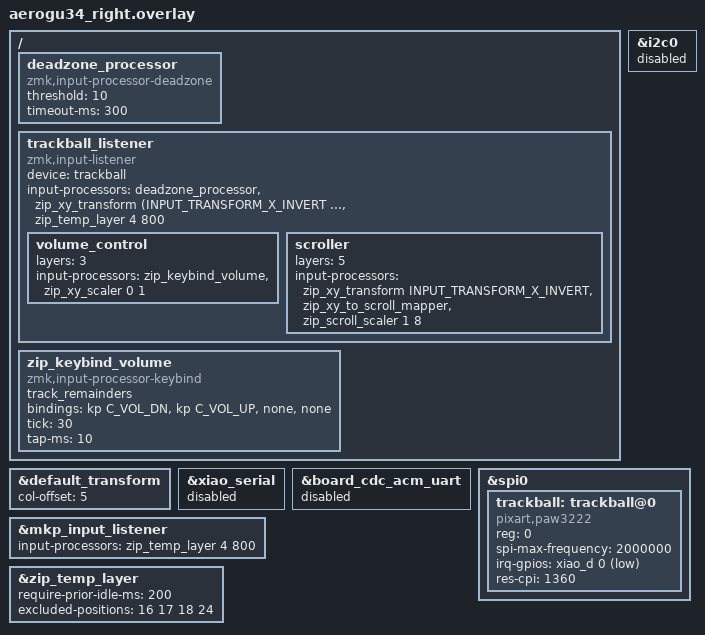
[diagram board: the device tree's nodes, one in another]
#include "aerogu34.dtsi"
#include <behaviors.dtsi>
#include <input/processors.dtsi>
#include <input/processors/runtime-input-processor.dtsi>
#include <input/processors/zmk-input-processor-keybind.dtsi>
#include <dt-bindings/zmk/runtime_input_processor.h>
#include <dt-bindings/zmk/input_transform.h>

&default_transform {
    col-offset = <5>;
};

&xiao_serial { status = "disabled"; };

/* Disable I2C0 to prevent conflict with SPI0 (same hardware peripheral). */
&i2c0 { status = "disabled"; };

/* Disable the board's default UART-over-USB-CDC-ACM endpoint.
 * Zephyr 4's xiao_ble board unconditionally adds a second CDC ACM USB
 * function for console/shell. With the studio-rpc-usb-uart snippet that
 * adds another CDC ACM for the Studio RPC channel, the device ends up
 * exposing two CDC ACMs and DYA Studio's Web Serial port-open fails
 * ("The port is already open" / wrong port chosen). We don't use the
 * console, so drop the node. */
&board_cdc_acm_uart { status = "disabled"; };

/ {
    deadzone_processor: deadzone_processor {
        compatible = "zmk,input-processor-deadzone";
        #input-processor-cells = <0>;
        threshold = <10>;
        timeout-ms = <300>;
    };

    trackball_listener: trackball_listener {
        compatible = "zmk,input-listener";
        device = <&trackball>;
        /* Chain order:
         *   deadzone  - filter sub-threshold noise
         *   xy_transform - invert both axes (sensor-mounting orientation)
         *   mouse_runtime - DYA Studio runtime config (CPI / snipe / etc)
         *   temp_layer 3 1000ms - auto-enable Mouse layer (3) on movement,
         *     turn back off after 1s of trackball inactivity
         *   scroll_runtime - convert XY -> scroll on layer 4 only */
        input-processors = <&deadzone_processor
                            &zip_xy_transform (INPUT_TRANSFORM_X_INVERT | INPUT_TRANSFORM_Y_INVERT)
                            &zip_temp_layer 4 800>;
    };
};

&spi0 {
    status = "okay";

    trackball: trackball@0 {
        status = "okay";
        compatible = "pixart,paw3222";
        reg = <0>;
        spi-max-frequency = <2000000>;
        irq-gpios = <&xiao_d 0 (GPIO_ACTIVE_LOW | GPIO_PULL_UP)>;
        /* Boot-time sensor CPI (counts per inch). Valid range 608-4826 in
         * steps of 38; driver rounds down. 800 maps to 21*38 = 798.
         * DYA Studio's runtime-input-processor can override at runtime. */
        res-cpi = <1360>;
    };
};

&mkp_input_listener { input-processors = <&zip_temp_layer 4 800>; };

&trackball_listener {
    volume_control {
        /* Keybind order is: right, left, down, up. */
        layers = <3>;
        /* Convert movement to volume keys first, then zero the relative
         * event so it cannot reach the normal mouse-pointer path. */
        input-processors = <&zip_keybind_volume
                            &zip_xy_scaler 0 1>;
    };

    scroller {
        layers = <5>;
        input-processors =
            <&zip_xy_transform INPUT_TRANSFORM_X_INVERT>,
            //スクロール方向を逆転,,,,,,,,,,,,,,
            <&zip_xy_to_scroll_mapper>,
            <&zip_scroll_scaler 1 8>;
    };
};

/ {
    zip_keybind_volume: zip_keybind_volume {
        compatible = "zmk,input-processor-keybind";
        #input-processor-cells = <0>;
        track_remainders;
        /* Sensor X is inverted: right raises volume, left lowers it. */
        bindings = <&kp C_VOL_DN>,
                   <&kp C_VOL_UP>,
                   <&none>,
                   <&none>;
        tick = <30>;
        tap-ms = <10>;
    };
};

&zip_temp_layer
{
    require-prior-idle-ms = <200>;
    excluded-positions = <
        16 // J
        17 // K
        18 // ;
        24 // Ctrl
        >;
};
